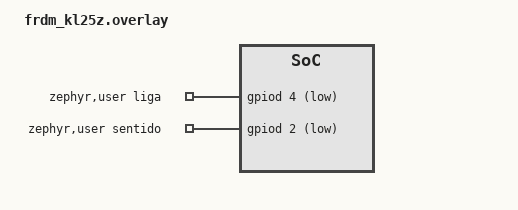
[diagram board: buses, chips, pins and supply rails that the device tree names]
/* Overlay da FRDM-KL25Z - tracker solar REAL (mega_context/).

   ⚠️ Depois de mexer aqui, APAGUE a pasta .pio/ antes de compilar: o
   PlatformIO nao regenera o devicetree so porque o overlay mudou, e o build
   segue com os nos antigos ("no nao encontrado" em DT_PATH/DT_NODELABEL).
   Ver mega_context/CLAUDE.md, secao "Armadilhas do ambiente".

   O ADC0 e o GPIOD ja vem habilitados pelo devicetree da placa. O
   potenciometro (PTC2 = A4 = ADC0_SE11) e configurado em tempo de execucao
   por lib/potenciometro, entao nao precisa de no aqui. */

/ {
    zephyr,user {
        /* Reles do motor - mega_context/circuito.md e mega_context/main_adr.md.

           GPIO_ACTIVE_LOW porque o modulo de reles LIGA quando a entrada IN
           recebe GND. O codigo escreve 1 = rele ligado, e o Zephyr poe 0 V no
           pino. Trocar para ACTIVE_HIGH aqui inverte TUDO: o motor ligaria no
           boot e no comando de parar. */
        liga-gpios    = <&gpiod 4 GPIO_ACTIVE_LOW>;  /* PTD4 = D2  -> R1 (LIGA)         */
        sentido-gpios = <&gpiod 2 GPIO_ACTIVE_LOW>;  /* PTD2 = D11 -> R2 e R3 (SENTIDO) */
    };
};
